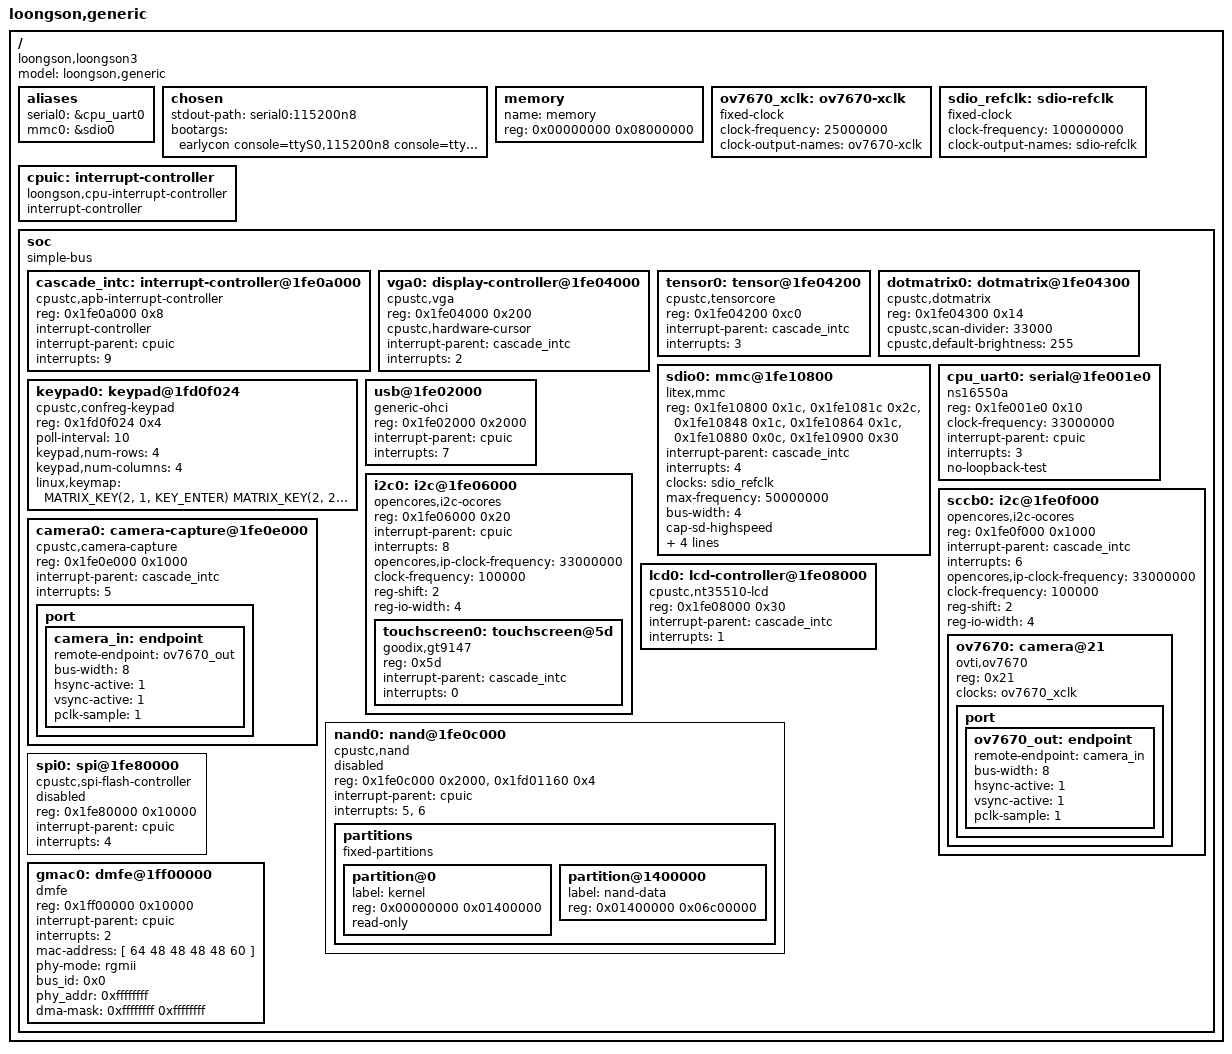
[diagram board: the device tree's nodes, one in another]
// SPDX-License-Identifier: GPL-2.0
/dts-v1/;

#include <dt-bindings/input/input.h>

/ {
	model = "loongson,generic";
	compatible = "loongson,loongson3";
	#address-cells = <1>;
	#size-cells = <1>;

	aliases {
		serial0 = &cpu_uart0;
		mmc0 = &sdio0;
	};

	chosen {
		stdout-path = "serial0:115200n8";
		bootargs = "earlycon console=ttyS0,115200n8 console=tty0 consoleblank=0";
	};

	memory {
		name = "memory";
		device_type = "memory";
		reg = <0x00000000  0x08000000>;
	};

	ov7670_xclk: ov7670-xclk {
		compatible = "fixed-clock";
		#clock-cells = <0>;
		clock-frequency = <25000000>;
		clock-output-names = "ov7670-xclk";
	};

	sdio_refclk: sdio-refclk {
		compatible = "fixed-clock";
		#clock-cells = <0>;
		clock-frequency = <100000000>;
		clock-output-names = "sdio-refclk";
	};

	cpuic: interrupt-controller {
		compatible = "loongson,cpu-interrupt-controller";
		interrupt-controller;
		#interrupt-cells = <1>;
	};

	soc {
		compatible = "simple-bus";
		#address-cells = <1>;
		#size-cells = <1>;
		ranges = <0x10000000 0x10000000 0x10000000>;

		/*
		 * CPU hwirq 2..9 correspond to HWI0..HWI7. HWI7 is the
		 * parent interrupt of the 8-input APB interrupt controller.
		 */
		cascade_intc: interrupt-controller@1fe0a000 {
			compatible = "cpustc,apb-interrupt-controller";
			reg = <0x1fe0a000 0x8>;
			interrupt-controller;
			#interrupt-cells = <1>;
			interrupt-parent = <&cpuic>;
			interrupts = <9>;
			interrupt-names = "cascade";

			/* input 0..6: touch, LCD, VGA, TensorCore, SDIO, Camera, SCCB */
		};

		vga0: display-controller@1fe04000 {
			compatible = "cpustc,vga";
			reg = <0x1fe04000 0x200>;
			cpustc,hardware-cursor;
			interrupt-parent = <&cascade_intc>;
			interrupts = <2>;
			interrupt-names = "vblank";
		};

		tensor0: tensor@1fe04200 {
			compatible = "cpustc,tensorcore";
			reg = <0x1fe04200 0xc0>;
			interrupt-parent = <&cascade_intc>;
			interrupts = <3>;
			interrupt-names = "completion";
			status = "okay";
		};

		dotmatrix0: dotmatrix@1fe04300 {
			compatible = "cpustc,dotmatrix";
			reg = <0x1fe04300 0x14>;
			cpustc,scan-divider = <33000>;
			cpustc,default-brightness = <255>;
			status = "okay";
		};

		sdio0: mmc@1fe10800 {
			compatible = "litex,mmc";
			reg = <0x1fe10800 0x1c>,
			      <0x1fe1081c 0x2c>,
			      <0x1fe10848 0x1c>,
			      <0x1fe10864 0x1c>,
			      <0x1fe10880 0x0c>,
			      <0x1fe10900 0x30>;
			reg-names = "phy", "core", "reader", "writer", "irq", "sg";
			interrupt-parent = <&cascade_intc>;
			interrupts = <4>;
			interrupt-names = "controller";
			clocks = <&sdio_refclk>;
			max-frequency = <50000000>;
			bus-width = <4>;
			cap-sd-highspeed;
			no-1-8-v;
			disable-wp;
			no-sdio;
			no-mmc;
			status = "okay";
		};

		cpu_uart0: serial@1fe001e0 {
			compatible = "ns16550a";
			reg = <0x1fe001e0  0x10>;
			clock-frequency = <33000000>;
			interrupt-parent = <&cpuic>;
			interrupts = <3>;
			no-loopback-test;
		};

		keypad0: keypad@1fd0f024 {
			compatible = "cpustc,confreg-keypad";
			reg = <0x1fd0f024 0x4>;
			poll-interval = <10>;
			keypad,num-rows = <4>;
			keypad,num-columns = <4>;
			linux,keymap = <MATRIX_KEY(2, 1, KEY_ENTER)
					MATRIX_KEY(2, 2, KEY_UP)
					MATRIX_KEY(2, 3, KEY_SPACE)
					MATRIX_KEY(3, 1, KEY_LEFT)
					MATRIX_KEY(3, 2, KEY_DOWN)
					MATRIX_KEY(3, 3, KEY_RIGHT)>;
			status = "okay";
		};

		usb@1fe02000 {
			compatible = "generic-ohci";
			reg = <0x1fe02000 0x2000>;
			interrupt-parent = <&cpuic>;
			interrupts = <7>;
		};

		i2c0: i2c@1fe06000 {
			compatible = "opencores,i2c-ocores";
			reg = <0x1fe06000 0x20>;
			#address-cells = <1>;
			#size-cells = <0>;
			interrupt-parent = <&cpuic>;
			interrupts = <8>;
			opencores,ip-clock-frequency = <33000000>;
			clock-frequency = <100000>;
			reg-shift = <2>;
			reg-io-width = <4>;

			touchscreen0: touchscreen@5d {
				compatible = "goodix,gt9147";
				reg = <0x5d>;
				interrupt-parent = <&cascade_intc>;
				interrupts = <0>;
				status = "okay";
			};
		};

		sccb0: i2c@1fe0f000 {
			compatible = "opencores,i2c-ocores";
			reg = <0x1fe0f000 0x1000>;
			#address-cells = <1>;
			#size-cells = <0>;
			interrupt-parent = <&cascade_intc>;
			interrupts = <6>;
			opencores,ip-clock-frequency = <33000000>;
			clock-frequency = <100000>;
			reg-shift = <2>;
			reg-io-width = <4>;

			ov7670: camera@21 {
				compatible = "ovti,ov7670";
				reg = <0x21>;
				clocks = <&ov7670_xclk>;
				clock-names = "xclk";

				port {
					ov7670_out: endpoint {
						remote-endpoint = <&camera_in>;
						bus-width = <8>;
						hsync-active = <1>;
						vsync-active = <1>;
						pclk-sample = <1>;
					};
				};
			};
		};

		camera0: camera-capture@1fe0e000 {
			compatible = "cpustc,camera-capture";
			reg = <0x1fe0e000 0x1000>;
			interrupt-parent = <&cascade_intc>;
			interrupts = <5>;
			interrupt-names = "completion";
			status = "okay";

			port {
				camera_in: endpoint {
					remote-endpoint = <&ov7670_out>;
					bus-width = <8>;
					hsync-active = <1>;
					vsync-active = <1>;
					pclk-sample = <1>;
				};
			};
		};

		lcd0: lcd-controller@1fe08000 {
			compatible = "cpustc,nt35510-lcd";
			reg = <0x1fe08000 0x30>;
			interrupt-parent = <&cascade_intc>;
			interrupts = <1>;
			interrupt-names = "event";
			status = "okay";
		};

		nand0: nand@1fe0c000 {
			compatible = "cpustc,nand";
			reg = <0x1fe0c000 0x2000>,
			      <0x1fd01160 0x4>;
			reg-names = "nand", "dma-order";
			interrupt-parent = <&cpuic>;
			interrupts = <5>, <6>;
			interrupt-names = "nand", "dma";
			status = "disabled";

			partitions {
				compatible = "fixed-partitions";
				#address-cells = <1>;
				#size-cells = <1>;

				partition@0 {
					label = "kernel";
					reg = <0x00000000 0x01400000>;
					read-only;
				};

				partition@1400000 {
					label = "nand-data";
					reg = <0x01400000 0x06c00000>;
				};
			};
		};

		spi0: spi@1fe80000 {
			compatible = "cpustc,spi-flash-controller";
			reg = <0x1fe80000 0x10000>;
			interrupt-parent = <&cpuic>;
			interrupts = <4>;
			status = "disabled";
		};

		gmac0: dmfe@1ff00000 {
			compatible = "dmfe";
			reg = <0x1ff00000 0x10000>;
			interrupt-parent = <&cpuic>;
			interrupts = <2>;
			interrupt-names = "macirq";
			mac-address = [ 64 48 48 48 48 60 ];/* [>mac 64:48:48:48:48:60 <]*/
			phy-mode = "rgmii";
			bus_id = <0x0>;
			phy_addr = <0xffffffff>;
			dma-mask = <0xffffffff 0xffffffff>;
		};
	};
};
